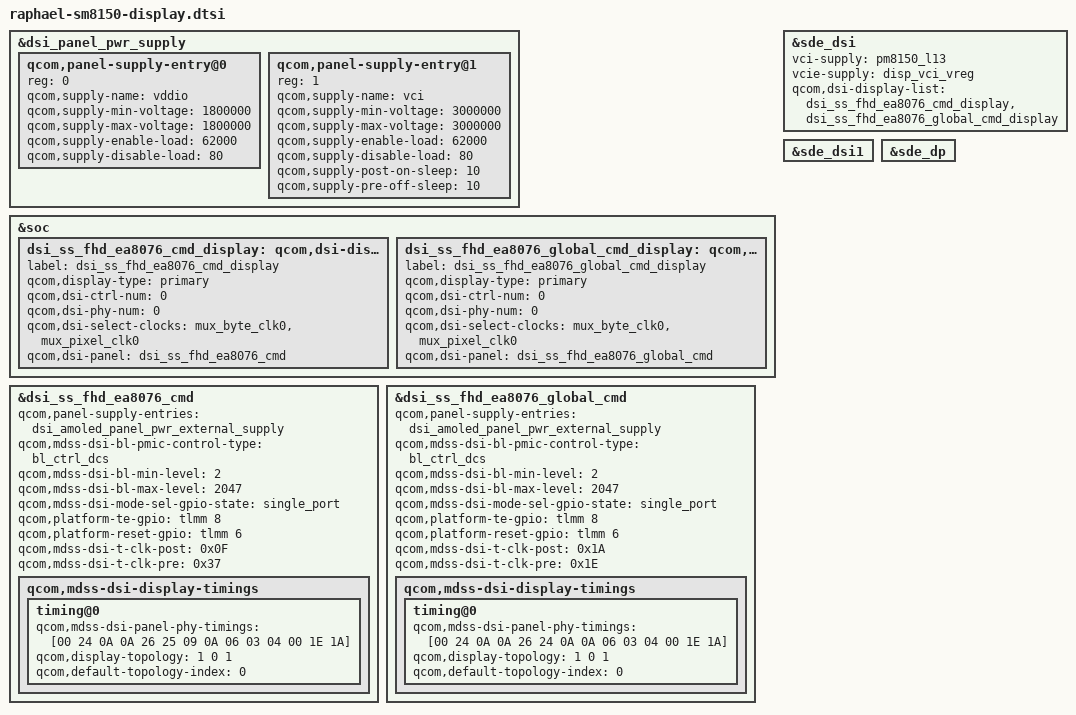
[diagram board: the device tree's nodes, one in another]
/* Copyright (c) 2020, The Linux Foundation. All rights reserved.
 *
 * This program is free software; you can redistribute it and/or modify
 * it under the terms of the GNU General Public License version 2 and
 * only version 2 as published by the Free Software Foundation.
 *
 * This program is distributed in the hope that it will be useful,
 * but WITHOUT ANY WARRANTY; without even the implied warranty of
 * MERCHANTABILITY or FITNESS FOR A PARTICULAR PURPOSE.  See the
 * GNU General Public License for more details.
 */

#include "display/dsi-panel-ss-fhd-ea8076-cmd.dtsi"
#include "display/dsi-panel-ss-fhd-ea8076-global-cmd.dtsi"

&dsi_panel_pwr_supply {
	qcom,panel-supply-entry@0 {
		reg = <0>;
		qcom,supply-name = "vddio";
		qcom,supply-min-voltage = <1800000>;
		qcom,supply-max-voltage = <1800000>;
		qcom,supply-enable-load = <62000>;
		qcom,supply-disable-load = <80>;
	};

	qcom,panel-supply-entry@1 {
		reg = <1>;
		qcom,supply-name = "vci";
		qcom,supply-min-voltage = <3000000>;
		qcom,supply-max-voltage = <3000000>;
		qcom,supply-enable-load = <62000>;
		qcom,supply-disable-load = <80>;
		qcom,supply-post-on-sleep = <10>;
		qcom,supply-pre-off-sleep = <10>;
	};
};

&soc {
	dsi_ss_fhd_ea8076_cmd_display: qcom,dsi-display@24 {
		label = "dsi_ss_fhd_ea8076_cmd_display";
		qcom,display-type = "primary";

		qcom,dsi-ctrl-num = <0>;
		qcom,dsi-phy-num = <0>;
		qcom,dsi-select-clocks = "mux_byte_clk0", "mux_pixel_clk0";

		qcom,dsi-panel = <&dsi_ss_fhd_ea8076_cmd>;
	};

	dsi_ss_fhd_ea8076_global_cmd_display: qcom,dsi-display@25 {
		label = "dsi_ss_fhd_ea8076_global_cmd_display";
		qcom,display-type = "primary";

		qcom,dsi-ctrl-num = <0>;
		qcom,dsi-phy-num = <0>;
		qcom,dsi-select-clocks = "mux_byte_clk0", "mux_pixel_clk0";

		qcom,dsi-panel = <&dsi_ss_fhd_ea8076_global_cmd>;
	};
};

&sde_dsi {
	vci-supply = <&pm8150_l13>;
	vcie-supply = <&disp_vci_vreg>;

	qcom,dsi-display-list =
		<&dsi_ss_fhd_ea8076_cmd_display
		&dsi_ss_fhd_ea8076_global_cmd_display>;
};

&sde_dsi1 {
	/delete-property/ vdd-supply;
};

&sde_dp {
	/delete-property/ qcom,dp-aux-switch;
};

&dsi_ss_fhd_ea8076_cmd {
	qcom,panel-supply-entries = <&dsi_amoled_panel_pwr_external_supply>;
	qcom,mdss-dsi-bl-pmic-control-type = "bl_ctrl_dcs";
	qcom,mdss-dsi-bl-min-level = <2>;
	qcom,mdss-dsi-bl-max-level = <2047>;
	qcom,mdss-dsi-mode-sel-gpio-state = "single_port";
	qcom,platform-te-gpio = <&tlmm 8 0>;
	qcom,platform-reset-gpio = <&tlmm 6 0>;
	qcom,mdss-dsi-t-clk-post = <0x0F>;
	qcom,mdss-dsi-t-clk-pre = <0x37>;
	qcom,mdss-dsi-display-timings {
		timing@0{
			qcom,mdss-dsi-panel-phy-timings = [00 24 0A 0A 26 25 09
				0A 06 03 04 00 1E 1A];
			qcom,display-topology = <1 0 1>;
			qcom,default-topology-index = <0>;
		};
	};
};

&dsi_ss_fhd_ea8076_global_cmd {
	qcom,panel-supply-entries = <&dsi_amoled_panel_pwr_external_supply>;
	qcom,mdss-dsi-bl-pmic-control-type = "bl_ctrl_dcs";
	qcom,mdss-dsi-bl-min-level = <2>;
	qcom,mdss-dsi-bl-max-level = <2047>;
	qcom,mdss-dsi-mode-sel-gpio-state = "single_port";
	qcom,platform-te-gpio = <&tlmm 8 0>;
	qcom,platform-reset-gpio = <&tlmm 6 0>;
	qcom,mdss-dsi-t-clk-post = <0x1A>;
	qcom,mdss-dsi-t-clk-pre = <0x1E>;
	qcom,mdss-dsi-display-timings {
		timing@0{
			qcom,mdss-dsi-panel-phy-timings = [00 24 0A 0A 26 24 0A
				0A 06 03 04 00 1E 1A];
			qcom,display-topology = <1 0 1>;
			qcom,default-topology-index = <0>;
		};
	};
};
